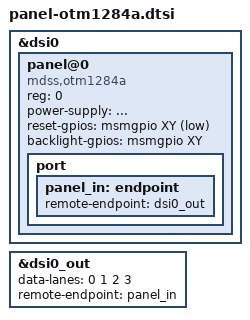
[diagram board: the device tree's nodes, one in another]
&dsi0 {
	panel@0 {
		compatible = "mdss,otm1284a";
		reg = <0>;

		power-supply = <&...>;
		reset-gpios = <&msmgpio XY GPIO_ACTIVE_LOW>;
		backlight-gpios = <&msmgpio XY GPIO_ACTIVE_HIGH>;

		port {
			panel_in: endpoint {
				remote-endpoint = <&dsi0_out>;
			};
		};
	};
};

&dsi0_out {
	data-lanes = <0 1 2 3>;
	remote-endpoint = <&panel_in>;
};
